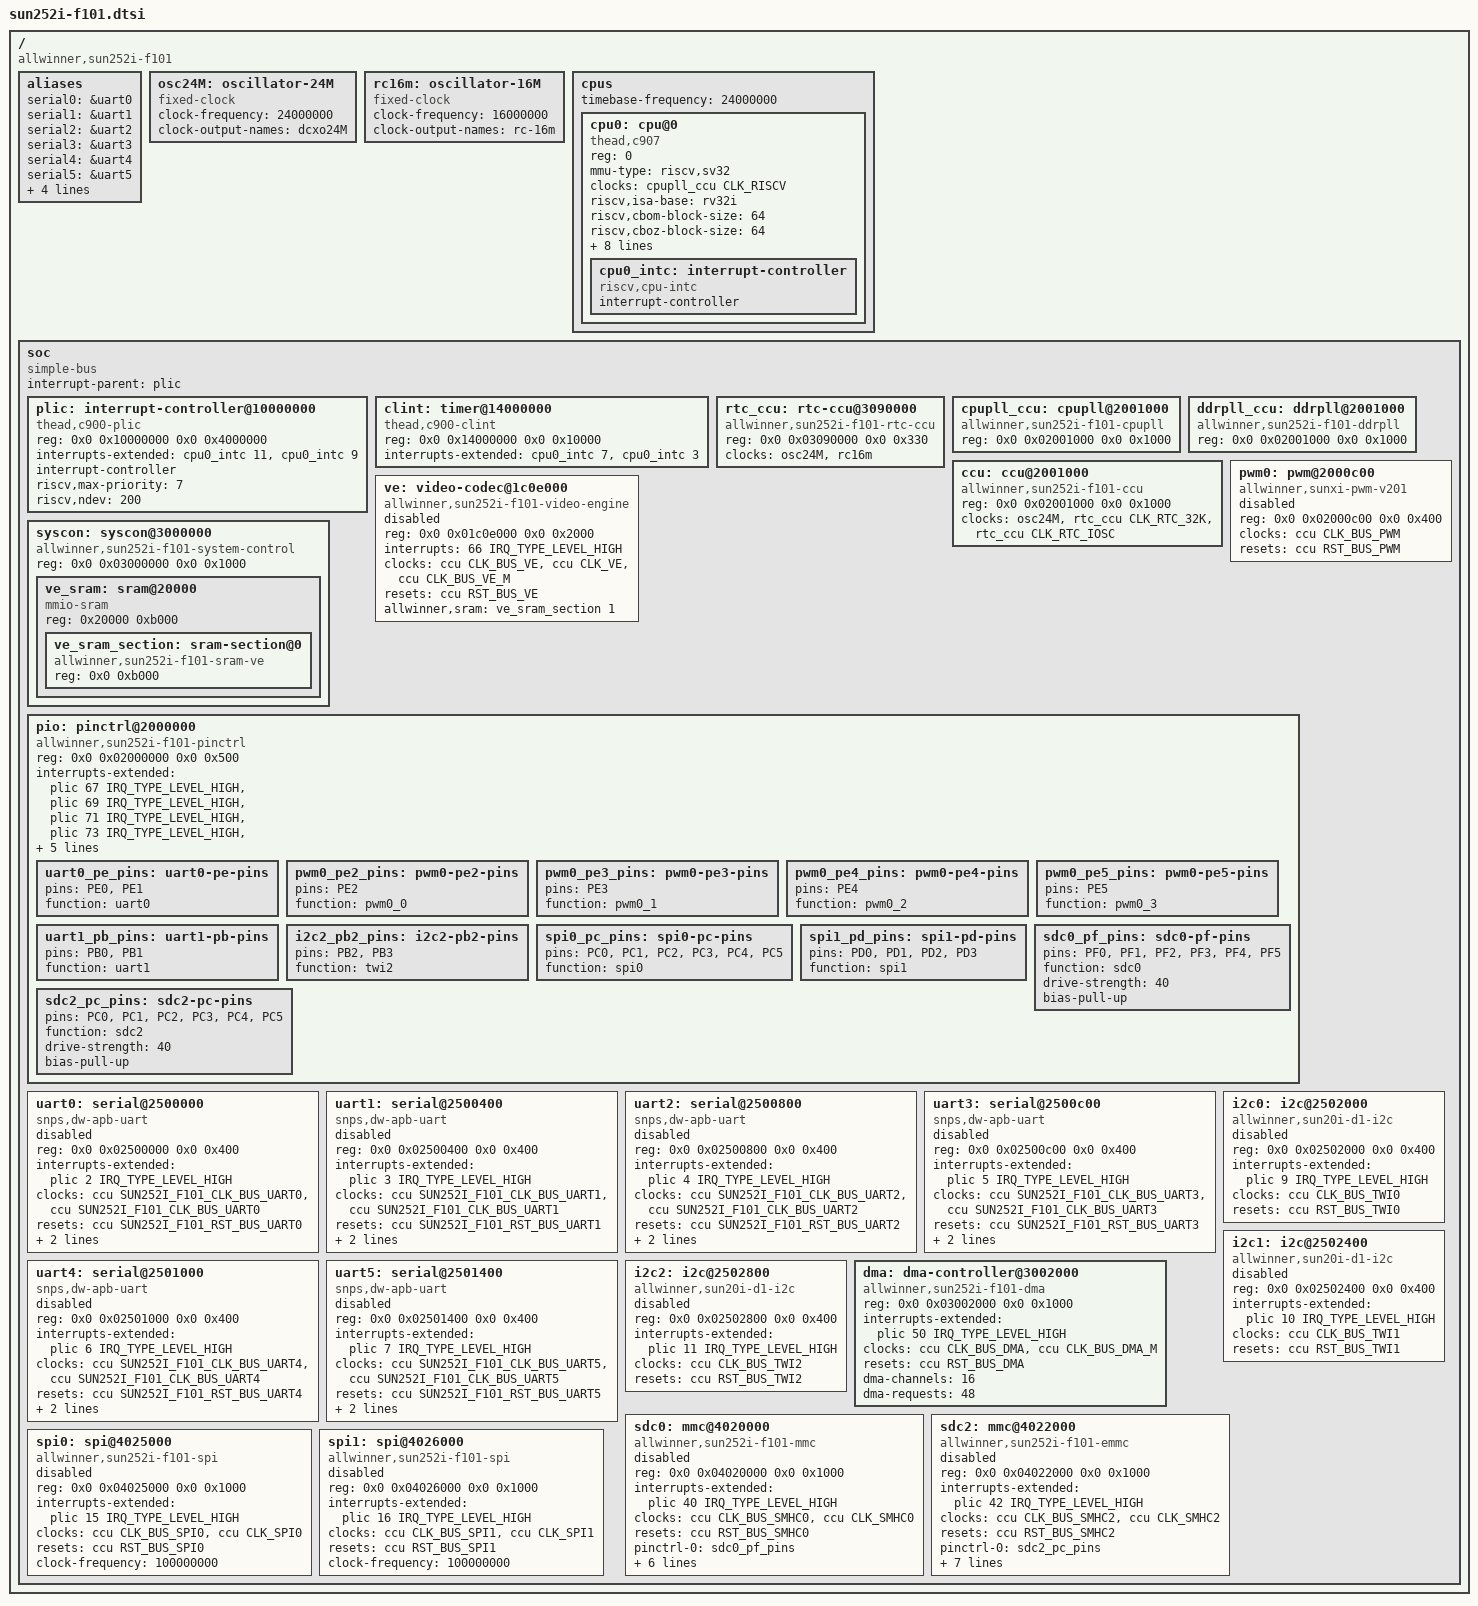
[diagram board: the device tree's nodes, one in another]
// SPDX-License-Identifier: GPL-2.0-only OR MIT

#include <dt-bindings/clock/sun252i-f101-ccu.h>
#include <dt-bindings/clock/sun252i-f101-cpupll.h>
#include <dt-bindings/clock/sun252i-f101-rtc.h>
#include <dt-bindings/gpio/gpio.h>
#include <dt-bindings/interrupt-controller/irq.h>
#include <dt-bindings/reset/sun252i-f101-ccu.h>

/ {
	#address-cells = <2>;
	#size-cells = <2>;
	compatible = "allwinner,sun252i-f101";

	aliases {
		serial0 = &uart0;
		serial1 = &uart1;
		serial2 = &uart2;
		serial3 = &uart3;
		serial4 = &uart4;
		serial5 = &uart5;
		spi0 = &spi0;
		spi1 = &spi1;
		mmc0 = &sdc0;
		mmc1 = &sdc2;
	};

	osc24M: oscillator-24M {
		compatible = "fixed-clock";
		#clock-cells = <0>;
		clock-frequency = <24000000>;
		clock-output-names = "dcxo24M";
	};

	rc16m: oscillator-16M {
		compatible = "fixed-clock";
		#clock-cells = <0>;
		clock-frequency = <16000000>;
		clock-output-names = "rc-16m";
	};

	cpus {
		#address-cells = <1>;
		#size-cells = <0>;
		timebase-frequency = <24000000>;

		cpu0: cpu@0 {
			compatible = "thead,c907", "riscv";
			device_type = "cpu";
			reg = <0>;
			mmu-type = "riscv,sv32";
			clocks = <&cpupll_ccu CLK_RISCV>;
			riscv,isa-base = "rv32i";
			riscv,cbom-block-size = <64>;
			riscv,cboz-block-size = <64>;
			riscv,isa-extensions = "i", "m", "a", "f", "d", "c", "v",
						     "zicbom", "zicbop", "zicboz", "zicond", "zihintntl",
						     "zihintpause", "zawrs", "zfa", "zfbfmin", "zfh", "zba",
						     "zbb", "zbc", "zbs", "sscofpmf", "zvfbfmin", "zvfbfwma",
						     "svinval", "svnapot", "svpbmt", "xtheadc", "xtheadvdot";
			d-cache-block-size = <64>;
			i-cache-block-size = <64>;

			cpu0_intc: interrupt-controller {
				compatible = "riscv,cpu-intc";
				interrupt-controller;
				#interrupt-cells = <1>;
			};
		};
	};

	soc: soc {
		compatible = "simple-bus";
		#address-cells = <2>;
		#size-cells = <2>;
		ranges;
		interrupt-parent = <&plic>;

		plic: interrupt-controller@10000000 {
			compatible = "thead,c900-plic";
			reg = <0x0 0x10000000 0x0 0x4000000>;
			interrupts-extended = <&cpu0_intc 11>, <&cpu0_intc 9>;
			interrupt-controller;
			#address-cells = <0>;
			#interrupt-cells = <2>;
			riscv,max-priority = <7>;
			riscv,ndev = <200>;
		};

		clint: timer@14000000 {
			compatible = "thead,c900-clint";
			reg = <0x0 0x14000000 0x0 0x10000>;
			interrupts-extended = <&cpu0_intc 7>, <&cpu0_intc 3>;
		};

		rtc_ccu: rtc-ccu@3090000 {
			compatible = "allwinner,sun252i-f101-rtc-ccu";
			reg = <0x0 0x03090000 0x0 0x330>;
			clocks = <&osc24M>, <&rc16m>;
			clock-names = "dcxo24M", "rc-16m";
			#clock-cells = <1>;
		};

		cpupll_ccu: cpupll@2001000 {
			compatible = "allwinner,sun252i-f101-cpupll";
			reg = <0x0 0x02001000 0x0 0x1000>;
			#clock-cells = <1>;
		};

		ddrpll_ccu: ddrpll@2001000 {
			compatible = "allwinner,sun252i-f101-ddrpll";
			reg = <0x0 0x02001000 0x0 0x1000>;
			#clock-cells = <1>;
		};

		ccu: ccu@2001000 {
			compatible = "allwinner,sun252i-f101-ccu";
			reg = <0x0 0x02001000 0x0 0x1000>;
			clocks = <&osc24M>, <&rtc_ccu CLK_RTC_32K>,
				 <&rtc_ccu CLK_RTC_IOSC>;
			clock-names = "hosc", "losc", "iosc";
			#clock-cells = <1>;
			#reset-cells = <1>;
		};

		ve: video-codec@1c0e000 {
			compatible = "allwinner,sun252i-f101-video-engine";
			reg = <0x0 0x01c0e000 0x0 0x2000>;
			interrupts = <66 IRQ_TYPE_LEVEL_HIGH>;
			clocks = <&ccu CLK_BUS_VE>,
				 <&ccu CLK_VE>,
				 <&ccu CLK_BUS_VE_M>;
			clock-names = "ahb", "mod", "ram";
			resets = <&ccu RST_BUS_VE>;
			allwinner,sram = <&ve_sram_section 1>;
			status = "disabled";
		};

		syscon: syscon@3000000 {
			compatible = "allwinner,sun252i-f101-system-control";
			reg = <0x0 0x03000000 0x0 0x1000>;
			#address-cells = <1>;
			#size-cells = <1>;
			ranges = <0x0 0x0 0x0 0x40000000>;

			ve_sram: sram@20000 {
				compatible = "mmio-sram";
				reg = <0x20000 0xb000>;
				#address-cells = <1>;
				#size-cells = <1>;
				ranges = <0 0x20000 0xb000>;

				ve_sram_section: sram-section@0 {
					compatible = "allwinner,sun252i-f101-sram-ve";
					reg = <0x0 0xb000>;
				};
			};
		};

		pwm0: pwm@2000c00 {
			compatible = "allwinner,sunxi-pwm-v201",
				     "allwinner,sun252i-f101-pwm";
			reg = <0x0 0x02000c00 0x0 0x400>;
			clocks = <&ccu CLK_BUS_PWM>;
			resets = <&ccu RST_BUS_PWM>;
			#pwm-cells = <3>;
			status = "disabled";
		};

		pio: pinctrl@2000000 {
			compatible = "allwinner,sun252i-f101-pinctrl";
			reg = <0x0 0x02000000 0x0 0x500>;
			interrupts-extended = <&plic 67 IRQ_TYPE_LEVEL_HIGH>,
					      <&plic 69 IRQ_TYPE_LEVEL_HIGH>,
					      <&plic 71 IRQ_TYPE_LEVEL_HIGH>,
					      <&plic 73 IRQ_TYPE_LEVEL_HIGH>,
					      <&plic 75 IRQ_TYPE_LEVEL_HIGH>,
					      <&plic 77 IRQ_TYPE_LEVEL_HIGH>;
			clocks = <&ccu SUN252I_F101_CLK_APB0>;
			gpio-controller;
			#gpio-cells = <3>;
			interrupt-controller;
			#interrupt-cells = <3>;

			uart0_pe_pins: uart0-pe-pins {
				pins = "PE0", "PE1";
				function = "uart0";
			};

			pwm0_pe2_pins: pwm0-pe2-pins {
				pins = "PE2";
				function = "pwm0_0";
			};

			pwm0_pe3_pins: pwm0-pe3-pins {
				pins = "PE3";
				function = "pwm0_1";
			};

			pwm0_pe4_pins: pwm0-pe4-pins {
				pins = "PE4";
				function = "pwm0_2";
			};

			pwm0_pe5_pins: pwm0-pe5-pins {
				pins = "PE5";
				function = "pwm0_3";
			};

			uart1_pb_pins: uart1-pb-pins {
				pins = "PB0", "PB1";
				function = "uart1";
			};

			i2c2_pb2_pins: i2c2-pb2-pins {
				pins = "PB2", "PB3";
				function = "twi2";
			};

			spi0_pc_pins: spi0-pc-pins {
				pins = "PC0", "PC1", "PC2", "PC3", "PC4", "PC5";
				function = "spi0";
			};

			spi1_pd_pins: spi1-pd-pins {
				pins = "PD0", "PD1", "PD2", "PD3";
				function = "spi1";
			};

			sdc0_pf_pins: sdc0-pf-pins {
				pins = "PF0", "PF1", "PF2", "PF3", "PF4", "PF5";
				function = "sdc0";
				drive-strength = <40>;
				bias-pull-up;
			};

			sdc2_pc_pins: sdc2-pc-pins {
				pins = "PC0", "PC1", "PC2", "PC3", "PC4", "PC5";
				function = "sdc2";
				drive-strength = <40>;
				bias-pull-up;
			};
		};

		uart0: serial@2500000 {
			compatible = "snps,dw-apb-uart";
			reg = <0x0 0x02500000 0x0 0x400>;
			interrupts-extended = <&plic 2 IRQ_TYPE_LEVEL_HIGH>;
			clocks = <&ccu SUN252I_F101_CLK_BUS_UART0>,
				 <&ccu SUN252I_F101_CLK_BUS_UART0>;
			clock-names = "baudclk", "apb_pclk";
			resets = <&ccu SUN252I_F101_RST_BUS_UART0>;
			reg-shift = <2>;
			reg-io-width = <4>;
			status = "disabled";
		};

		uart1: serial@2500400 {
			compatible = "snps,dw-apb-uart";
			reg = <0x0 0x02500400 0x0 0x400>;
			interrupts-extended = <&plic 3 IRQ_TYPE_LEVEL_HIGH>;
			clocks = <&ccu SUN252I_F101_CLK_BUS_UART1>,
				 <&ccu SUN252I_F101_CLK_BUS_UART1>;
			clock-names = "baudclk", "apb_pclk";
			resets = <&ccu SUN252I_F101_RST_BUS_UART1>;
			reg-shift = <2>;
			reg-io-width = <4>;
			status = "disabled";
		};

		uart2: serial@2500800 {
			compatible = "snps,dw-apb-uart";
			reg = <0x0 0x02500800 0x0 0x400>;
			interrupts-extended = <&plic 4 IRQ_TYPE_LEVEL_HIGH>;
			clocks = <&ccu SUN252I_F101_CLK_BUS_UART2>,
				 <&ccu SUN252I_F101_CLK_BUS_UART2>;
			clock-names = "baudclk", "apb_pclk";
			resets = <&ccu SUN252I_F101_RST_BUS_UART2>;
			reg-shift = <2>;
			reg-io-width = <4>;
			status = "disabled";
		};

		uart3: serial@2500c00 {
			compatible = "snps,dw-apb-uart";
			reg = <0x0 0x02500c00 0x0 0x400>;
			interrupts-extended = <&plic 5 IRQ_TYPE_LEVEL_HIGH>;
			clocks = <&ccu SUN252I_F101_CLK_BUS_UART3>,
				 <&ccu SUN252I_F101_CLK_BUS_UART3>;
			clock-names = "baudclk", "apb_pclk";
			resets = <&ccu SUN252I_F101_RST_BUS_UART3>;
			reg-shift = <2>;
			reg-io-width = <4>;
			status = "disabled";
		};

		uart4: serial@2501000 {
			compatible = "snps,dw-apb-uart";
			reg = <0x0 0x02501000 0x0 0x400>;
			interrupts-extended = <&plic 6 IRQ_TYPE_LEVEL_HIGH>;
			clocks = <&ccu SUN252I_F101_CLK_BUS_UART4>,
				 <&ccu SUN252I_F101_CLK_BUS_UART4>;
			clock-names = "baudclk", "apb_pclk";
			resets = <&ccu SUN252I_F101_RST_BUS_UART4>;
			reg-shift = <2>;
			reg-io-width = <4>;
			status = "disabled";
		};

		uart5: serial@2501400 {
			compatible = "snps,dw-apb-uart";
			reg = <0x0 0x02501400 0x0 0x400>;
			interrupts-extended = <&plic 7 IRQ_TYPE_LEVEL_HIGH>;
			clocks = <&ccu SUN252I_F101_CLK_BUS_UART5>,
				 <&ccu SUN252I_F101_CLK_BUS_UART5>;
			clock-names = "baudclk", "apb_pclk";
			resets = <&ccu SUN252I_F101_RST_BUS_UART5>;
			reg-shift = <2>;
			reg-io-width = <4>;
			status = "disabled";
		};

		i2c0: i2c@2502000 {
			compatible = "allwinner,sun20i-d1-i2c",
				     "allwinner,sun8i-v536-i2c",
				     "allwinner,sun6i-a31-i2c";
			reg = <0x0 0x02502000 0x0 0x400>;
			interrupts-extended = <&plic 9 IRQ_TYPE_LEVEL_HIGH>;
			clocks = <&ccu CLK_BUS_TWI0>;
			resets = <&ccu RST_BUS_TWI0>;
			status = "disabled";
			#address-cells = <1>;
			#size-cells = <0>;
		};

		i2c1: i2c@2502400 {
			compatible = "allwinner,sun20i-d1-i2c",
				     "allwinner,sun8i-v536-i2c",
				     "allwinner,sun6i-a31-i2c";
			reg = <0x0 0x02502400 0x0 0x400>;
			interrupts-extended = <&plic 10 IRQ_TYPE_LEVEL_HIGH>;
			clocks = <&ccu CLK_BUS_TWI1>;
			resets = <&ccu RST_BUS_TWI1>;
			status = "disabled";
			#address-cells = <1>;
			#size-cells = <0>;
		};

		i2c2: i2c@2502800 {
			compatible = "allwinner,sun20i-d1-i2c",
				     "allwinner,sun8i-v536-i2c",
				     "allwinner,sun6i-a31-i2c";
			reg = <0x0 0x02502800 0x0 0x400>;
			interrupts-extended = <&plic 11 IRQ_TYPE_LEVEL_HIGH>;
			clocks = <&ccu CLK_BUS_TWI2>;
			resets = <&ccu RST_BUS_TWI2>;
			status = "disabled";
			#address-cells = <1>;
			#size-cells = <0>;
		};

		dma: dma-controller@3002000 {
			compatible = "allwinner,sun252i-f101-dma",
				     "allwinner,sun20i-d1-dma";
			reg = <0x0 0x03002000 0x0 0x1000>;
			interrupts-extended = <&plic 50 IRQ_TYPE_LEVEL_HIGH>;
			clocks = <&ccu CLK_BUS_DMA>,
				 <&ccu CLK_BUS_DMA_M>;
			clock-names = "bus", "mbus";
			resets = <&ccu RST_BUS_DMA>;
			dma-channels = <16>;
			dma-requests = <48>;
			#dma-cells = <1>;
		};

		sdc0: mmc@4020000 {
			compatible = "allwinner,sun252i-f101-mmc";
			reg = <0x0 0x04020000 0x0 0x1000>;
			interrupts-extended = <&plic 40 IRQ_TYPE_LEVEL_HIGH>;
			clocks = <&ccu CLK_BUS_SMHC0>, <&ccu CLK_SMHC0>;
			clock-names = "ahb", "mmc";
			resets = <&ccu RST_BUS_SMHC0>;
			reset-names = "ahb";
			pinctrl-names = "default";
			pinctrl-0 = <&sdc0_pf_pins>;
			bus-width = <4>;
			max-frequency = <50000000>;
			cap-sd-highspeed;
			no-1-8-v;
			no-mmc;
			no-sdio;
			status = "disabled";
		};

		sdc2: mmc@4022000 {
			compatible = "allwinner,sun252i-f101-emmc";
			reg = <0x0 0x04022000 0x0 0x1000>;
			interrupts-extended = <&plic 42 IRQ_TYPE_LEVEL_HIGH>;
			clocks = <&ccu CLK_BUS_SMHC2>, <&ccu CLK_SMHC2>;
			clock-names = "ahb", "mmc";
			resets = <&ccu RST_BUS_SMHC2>;
			reset-names = "ahb";
			pinctrl-names = "default";
			pinctrl-0 = <&sdc2_pc_pins>;
			bus-width = <4>;
			max-frequency = <50000000>;
			cap-mmc-highspeed;
			no-1-8-v;
			no-sd;
			no-sdio;
			non-removable;
			status = "disabled";
		};

		spi0: spi@4025000 {
			#address-cells = <1>;
			#size-cells = <0>;
			compatible = "allwinner,sun252i-f101-spi",
				     "allwinner,sun50i-r329-spi";
			reg = <0x0 0x04025000 0x0 0x1000>;
			interrupts-extended = <&plic 15 IRQ_TYPE_LEVEL_HIGH>;
			clocks = <&ccu CLK_BUS_SPI0>,
				 <&ccu CLK_SPI0>;
			clock-names = "ahb", "mod";
			resets = <&ccu RST_BUS_SPI0>;
			clock-frequency = <100000000>;
			status = "disabled";
		};

		spi1: spi@4026000 {
			#address-cells = <1>;
			#size-cells = <0>;
			compatible = "allwinner,sun252i-f101-spi",
				     "allwinner,sun50i-r329-spi";
			reg = <0x0 0x04026000 0x0 0x1000>;
			interrupts-extended = <&plic 16 IRQ_TYPE_LEVEL_HIGH>;
			clocks = <&ccu CLK_BUS_SPI1>,
				 <&ccu CLK_SPI1>;
			clock-names = "ahb", "mod";
			resets = <&ccu RST_BUS_SPI1>;
			clock-frequency = <100000000>;
			status = "disabled";
		};
	};
};
